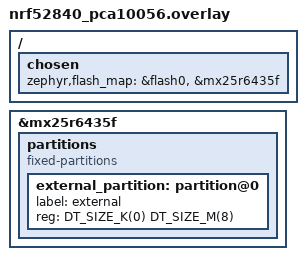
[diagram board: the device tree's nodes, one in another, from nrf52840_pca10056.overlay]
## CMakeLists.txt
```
cmake_minimum_required(VERSION 3.8.2)

macro(set_conf_file)
  set(CONF_FILE "prj.conf")
  if(EXISTS ${APPLICATION_SOURCE_DIR}/boards/${BOARD}.conf)
    list(APPEND CONF_FILE "${APPLICATION_SOURCE_DIR}/boards/${BOARD}.conf")
  endif()
  if(EXISTS ${APPLICATION_SOURCE_DIR}/debug.conf)
    list(APPEND CONF_FILE "${APPLICATION_SOURCE_DIR}/debug.conf")
  endif()
endmacro()

include($ENV{ZEPHYR_BASE}/cmake/app/boilerplate.cmake NO_POLICY_SCOPE)
project(spi_flash)

FILE(GLOB app_sources src/*.c)
target_sources(app PRIVATE ${app_sources})
```

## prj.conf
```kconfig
CONFIG_GPIO=y
CONFIG_FLASH=y
CONFIG_FILE_SYSTEM=y
CONFIG_FILE_SYSTEM_ZFFS=y
```

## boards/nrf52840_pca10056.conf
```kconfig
CONFIG_BT=n
CONFIG_BT_CTLR=n

CONFIG_QSPI_FLASH_NRF=y
CONFIG_ZFFS_AREA_ALIGNED_SIZE=4
CONFIG_MAIN_STACK_SIZE=2048
```

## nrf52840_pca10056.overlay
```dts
/ {
 	chosen {
		zephyr,flash_map = &flash0, &mx25r6435f;
	};
};

&mx25r6435f {
	partitions {
		compatible = "fixed-partitions";
		#address-cells = <1>;
		#size-cells = <1>;

 		external_partition: partition@0 {
			label = "external";
			reg = <DT_SIZE_K(0) DT_SIZE_M(8)>;
		};
	};
};
```

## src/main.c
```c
/*
 * Copyright (c) 2018 Findlay Feng
 *
 * SPDX-License-Identifier: Apache-2.0
 */

#include <zffs/zffs.h>
#include <fs.h>
#include <flash_map.h>
#include <misc/printk.h>
#include <zephyr.h>
#include <string.h>

#define ZFFS_ROOT_DIR "/zffs"

struct zffs_data zd;
struct zffs_area *area[3][ZFFS_CONFIG_AREA_MAX + 1];
struct fs_mount_t fs_mnt;

void main(void)
{
	int rc;

	if (flash_area_open(FLASH_AREA_EXTERNAL_ID,
			    (const struct flash_area **)&fs_mnt.storage_dev)) {
		return;
	}

	zd.area = area[0];
	zd.swap_area = area[1];
	zd.data_area = area[2];

	fs_mnt.type = FS_ZFFS;
	fs_mnt.mnt_point = ZFFS_ROOT_DIR;
	fs_mnt.fs_data = &zd;

	if ((rc = fs_mount(&fs_mnt)) != 0) {
		flash_area_close(fs_mnt.storage_dev);
		return;
	}

	fs_unmount(&fs_mnt);
	flash_area_close(fs_mnt.storage_dev);
}
```
